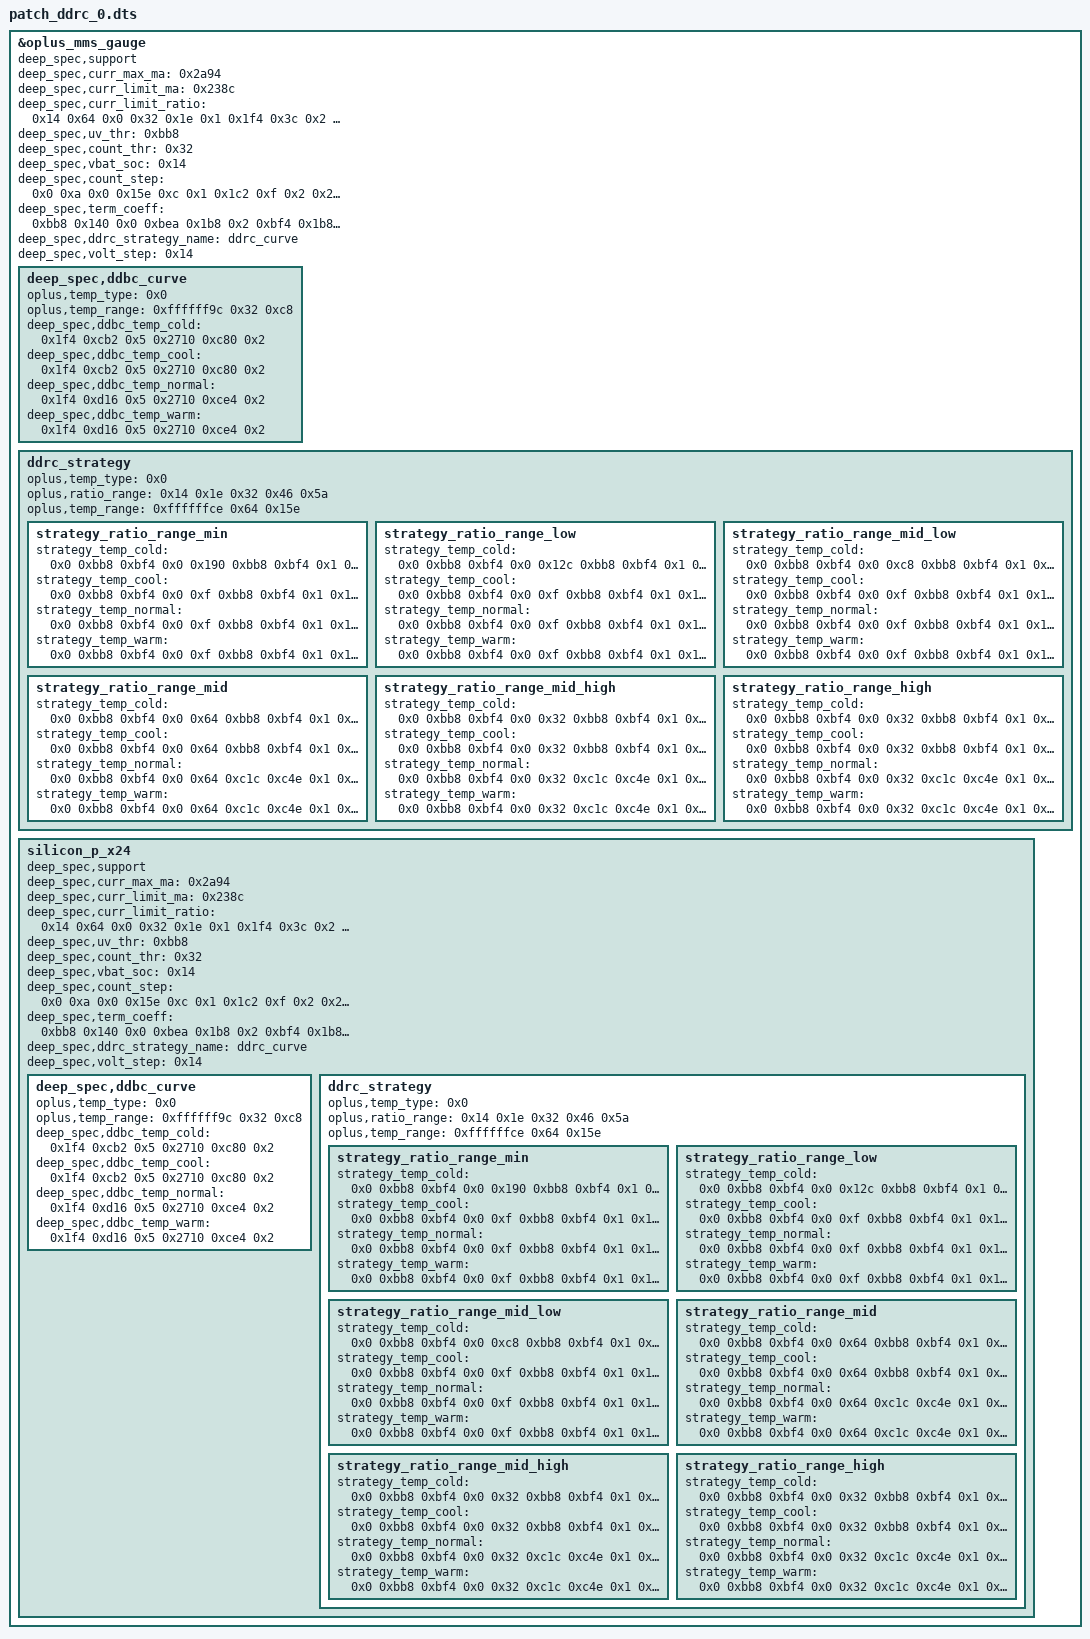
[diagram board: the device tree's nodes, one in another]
/dts-v1/;
/plugin/;

/ {
	fragment@0 {
		target = <&oplus_mms_gauge>;
		__overlay__ {
			deep_spec,support;
			deep_spec,curr_max_ma = <0x2a94>;
			deep_spec,curr_limit_ma = <0x238c>;
			deep_spec,curr_limit_ratio = <0x14 0x64 0x0 0x32 0x1e 0x1 0x1f4 0x3c 0x2 0x1f4 0x3c 0x3>;
			deep_spec,uv_thr = <0xbb8>;
			deep_spec,count_thr = <0x32>;
			deep_spec,vbat_soc = <0x14>;
			deep_spec,count_step = <0x0 0xa 0x0 0x15e 0xc 0x1 0x1c2 0xf 0x2 0x212 0x14 0x3>;
			deep_spec,term_coeff = <0xbb8 0x140 0x0 0xbea 0x1b8 0x2 0xbf4 0x1b8 0x2 0xc4e 0x21c 0x4 0xcb2 0x244 0x5 0xd16 0x258 0x7>;
			deep_spec,ddrc_strategy_name = "ddrc_curve";
			deep_spec,volt_step = <0x14>;
			
			deep_spec,ddbc_curve {
				oplus,temp_type = <0x0>;
				oplus,temp_range = <0xffffff9c 0x32 0xc8>;
				deep_spec,ddbc_temp_cold = <0x1f4 0xcb2 0x5 0x2710 0xc80 0x2>;
				deep_spec,ddbc_temp_cool = <0x1f4 0xcb2 0x5 0x2710 0xc80 0x2>;
				deep_spec,ddbc_temp_normal = <0x1f4 0xd16 0x5 0x2710 0xce4 0x2>;
				deep_spec,ddbc_temp_warm = <0x1f4 0xd16 0x5 0x2710 0xce4 0x2>;
			};
			
			ddrc_strategy {
				oplus,temp_type = <0x0>;
				oplus,ratio_range = <0x14 0x1e 0x32 0x46 0x5a>;
				oplus,temp_range = <0xffffffce 0x64 0x15e>;
				
				strategy_ratio_range_min {
					strategy_temp_cold = <0x0 0xbb8 0xbf4 0x0 0x190 0xbb8 0xbf4 0x1 0x320 0xbb8 0xbf4 0x2 0x4b0 0xc1c 0xc4e 0x3 0x640 0xc80 0xcb2 0x4 0x7d0 0xce4 0xd16 0x5>;
					strategy_temp_cool = <0x0 0xbb8 0xbf4 0x0 0xf 0xbb8 0xbf4 0x1 0x1f4 0xbb8 0xbf4 0x2 0x3e8 0xc1c 0xc4e 0x3 0x5dc 0xc80 0xcb2 0x4 0x7d0 0xce4 0xd16 0x5>;
					strategy_temp_normal = <0x0 0xbb8 0xbf4 0x0 0xf 0xbb8 0xbf4 0x1 0x1f4 0xc1c 0xc4e 0x2 0x3e8 0xc80 0xcb2 0x3 0x5dc 0xce4 0xd16 0x4>;
					strategy_temp_warm = <0x0 0xbb8 0xbf4 0x0 0xf 0xbb8 0xbf4 0x1 0x1f4 0xc1c 0xc4e 0x2 0x3e8 0xc80 0xcb2 0x3 0x5dc 0xce4 0xd16 0x4>;
				};
				
				strategy_ratio_range_low {
					strategy_temp_cold = <0x0 0xbb8 0xbf4 0x0 0x12c 0xbb8 0xbf4 0x1 0x258 0xbb8 0xbf4 0x2 0x384 0xc1c 0xc4e 0x3 0x4b0 0xc80 0xcb2 0x4 0x640 0xce4 0xd16 0x5>;
					strategy_temp_cool = <0x0 0xbb8 0xbf4 0x0 0xf 0xbb8 0xbf4 0x1 0x190 0xbb8 0xbf4 0x2 0x320 0xc1c 0xc4e 0x3 0x4b0 0xc80 0xcb2 0x4 0x640 0xce4 0xd16 0x5>;
					strategy_temp_normal = <0x0 0xbb8 0xbf4 0x0 0xf 0xbb8 0xbf4 0x1 0x190 0xc1c 0xc4e 0x2 0x320 0xc80 0xcb2 0x3 0x4b0 0xce4 0xd16 0x4>;
					strategy_temp_warm = <0x0 0xbb8 0xbf4 0x0 0xf 0xbb8 0xbf4 0x1 0x190 0xc1c 0xc4e 0x2 0x320 0xc80 0xcb2 0x3 0x4b0 0xce4 0xd16 0x4>;
				};
				
				strategy_ratio_range_mid_low {
					strategy_temp_cold = <0x0 0xbb8 0xbf4 0x0 0xc8 0xbb8 0xbf4 0x1 0x190 0xbb8 0xbf4 0x2 0x258 0xc1c 0xc4e 0x3 0x384 0xc80 0xcb2 0x4 0x4b0 0xce4 0xd16 0x5>;
					strategy_temp_cool = <0x0 0xbb8 0xbf4 0x0 0xf 0xbb8 0xbf4 0x1 0x12c 0xbb8 0xbf4 0x2 0x258 0xc1c 0xc4e 0x3 0x384 0xc80 0xcb2 0x4 0x4b0 0xce4 0xd16 0x5>;
					strategy_temp_normal = <0x0 0xbb8 0xbf4 0x0 0xf 0xbb8 0xbf4 0x1 0x12c 0xc1c 0xc4e 0x2 0x258 0xc80 0xcb2 0x3 0x384 0xce4 0xd16 0x4>;
					strategy_temp_warm = <0x0 0xbb8 0xbf4 0x0 0xf 0xbb8 0xbf4 0x1 0x12c 0xc1c 0xc4e 0x2 0x258 0xc80 0xcb2 0x3 0x384 0xce4 0xd16 0x4>;
				};
				
				strategy_ratio_range_mid {
					strategy_temp_cold = <0x0 0xbb8 0xbf4 0x0 0x64 0xbb8 0xbf4 0x1 0x12c 0xbb8 0xbf4 0x2 0x1f4 0xc1c 0xc4e 0x3 0x2bc 0xc80 0xcb2 0x4 0x384 0xce4 0xd16 0x5>;
					strategy_temp_cool = <0x0 0xbb8 0xbf4 0x0 0x64 0xbb8 0xbf4 0x1 0x12c 0xc1c 0xc4e 0x2 0x258 0xc80 0xcb2 0x3 0x384 0xce4 0xd16 0x4>;
					strategy_temp_normal = <0x0 0xbb8 0xbf4 0x0 0x64 0xc1c 0xc4e 0x1 0x12c 0xc80 0xcb2 0x2 0x258 0xce4 0xd16 0x3>;
					strategy_temp_warm = <0x0 0xbb8 0xbf4 0x0 0x64 0xc1c 0xc4e 0x1 0x12c 0xc80 0xcb2 0x2 0x258 0xce4 0xd16 0x3>;
				};
				
				strategy_ratio_range_mid_high {
					strategy_temp_cold = <0x0 0xbb8 0xbf4 0x0 0x32 0xbb8 0xbf4 0x1 0x64 0xbb8 0xbf4 0x2 0x96 0xc1c 0xc4e 0x3 0x12c 0xc80 0xcb2 0x4 0x1f4 0xce4 0xd16 0x5>;
					strategy_temp_cool = <0x0 0xbb8 0xbf4 0x0 0x32 0xbb8 0xbf4 0x1 0x64 0xc1c 0xc4e 0x2 0x96 0xc80 0xcb2 0x3 0x12c 0xce4 0xd16 0x4>;
					strategy_temp_normal = <0x0 0xbb8 0xbf4 0x0 0x32 0xc1c 0xc4e 0x1 0x64 0xc80 0xcb2 0x2 0x96 0xce4 0xd16 0x3>;
					strategy_temp_warm = <0x0 0xbb8 0xbf4 0x0 0x32 0xc1c 0xc4e 0x1 0x64 0xc80 0xcb2 0x2 0x96 0xce4 0xd16 0x3>;
				};
				
				strategy_ratio_range_high {
					strategy_temp_cold = <0x0 0xbb8 0xbf4 0x0 0x32 0xbb8 0xbf4 0x1 0x64 0xbb8 0xbf4 0x2 0x96 0xc1c 0xc4e 0x3 0x12c 0xc80 0xcb2 0x4 0x1f4 0xce4 0xd16 0x5>;
					strategy_temp_cool = <0x0 0xbb8 0xbf4 0x0 0x32 0xbb8 0xbf4 0x1 0x64 0xc1c 0xc4e 0x2 0x96 0xc80 0xcb2 0x3 0x12c 0xce4 0xd16 0x4>;
					strategy_temp_normal = <0x0 0xbb8 0xbf4 0x0 0x32 0xc1c 0xc4e 0x1 0x64 0xc80 0xcb2 0x2 0x96 0xce4 0xd16 0x3>;
					strategy_temp_warm = <0x0 0xbb8 0xbf4 0x0 0x32 0xc1c 0xc4e 0x1 0x64 0xc80 0xcb2 0x2 0x96 0xce4 0xd16 0x3>;
				};
			};
			
			silicon_p_x24 {
				deep_spec,support;
				deep_spec,curr_max_ma = <0x2a94>;
				deep_spec,curr_limit_ma = <0x238c>;
				deep_spec,curr_limit_ratio = <0x14 0x64 0x0 0x32 0x1e 0x1 0x1f4 0x3c 0x2 0x1f4 0x3c 0x3>;
				deep_spec,uv_thr = <0xbb8>;
				deep_spec,count_thr = <0x32>;
				deep_spec,vbat_soc = <0x14>;
				deep_spec,count_step = <0x0 0xa 0x0 0x15e 0xc 0x1 0x1c2 0xf 0x2 0x212 0x14 0x3>;
				deep_spec,term_coeff = <0xbb8 0x140 0x0 0xbea 0x1b8 0x2 0xbf4 0x1b8 0x2 0xc4e 0x21c 0x4 0xcb2 0x244 0x5 0xd16 0x258 0x7>;
				deep_spec,ddrc_strategy_name = "ddrc_curve";
				deep_spec,volt_step = <0x14>;
				
				deep_spec,ddbc_curve {
					oplus,temp_type = <0x0>;
					oplus,temp_range = <0xffffff9c 0x32 0xc8>;
					deep_spec,ddbc_temp_cold = <0x1f4 0xcb2 0x5 0x2710 0xc80 0x2>;
					deep_spec,ddbc_temp_cool = <0x1f4 0xcb2 0x5 0x2710 0xc80 0x2>;
					deep_spec,ddbc_temp_normal = <0x1f4 0xd16 0x5 0x2710 0xce4 0x2>;
					deep_spec,ddbc_temp_warm = <0x1f4 0xd16 0x5 0x2710 0xce4 0x2>;
				};
				
				ddrc_strategy {
					oplus,temp_type = <0x0>;
					oplus,ratio_range = <0x14 0x1e 0x32 0x46 0x5a>;
					oplus,temp_range = <0xffffffce 0x64 0x15e>;
					
					strategy_ratio_range_min {
						strategy_temp_cold = <0x0 0xbb8 0xbf4 0x0 0x190 0xbb8 0xbf4 0x1 0x320 0xbb8 0xbf4 0x2 0x4b0 0xc1c 0xc4e 0x3 0x640 0xc80 0xcb2 0x4 0x7d0 0xce4 0xd16 0x5>;
						strategy_temp_cool = <0x0 0xbb8 0xbf4 0x0 0xf 0xbb8 0xbf4 0x1 0x1f4 0xbb8 0xbf4 0x2 0x3e8 0xc1c 0xc4e 0x3 0x5dc 0xc80 0xcb2 0x4 0x7d0 0xce4 0xd16 0x5>;
						strategy_temp_normal = <0x0 0xbb8 0xbf4 0x0 0xf 0xbb8 0xbf4 0x1 0x1f4 0xc1c 0xc4e 0x2 0x3e8 0xc80 0xcb2 0x3 0x5dc 0xce4 0xd16 0x4>;
						strategy_temp_warm = <0x0 0xbb8 0xbf4 0x0 0xf 0xbb8 0xbf4 0x1 0x1f4 0xc1c 0xc4e 0x2 0x3e8 0xc80 0xcb2 0x3 0x5dc 0xce4 0xd16 0x4>;
					};
					
					strategy_ratio_range_low {
						strategy_temp_cold = <0x0 0xbb8 0xbf4 0x0 0x12c 0xbb8 0xbf4 0x1 0x258 0xbb8 0xbf4 0x2 0x384 0xc1c 0xc4e 0x3 0x4b0 0xc80 0xcb2 0x4 0x640 0xce4 0xd16 0x5>;
						strategy_temp_cool = <0x0 0xbb8 0xbf4 0x0 0xf 0xbb8 0xbf4 0x1 0x190 0xbb8 0xbf4 0x2 0x320 0xc1c 0xc4e 0x3 0x4b0 0xc80 0xcb2 0x4 0x640 0xce4 0xd16 0x5>;
						strategy_temp_normal = <0x0 0xbb8 0xbf4 0x0 0xf 0xbb8 0xbf4 0x1 0x190 0xc1c 0xc4e 0x2 0x320 0xc80 0xcb2 0x3 0x4b0 0xce4 0xd16 0x4>;
						strategy_temp_warm = <0x0 0xbb8 0xbf4 0x0 0xf 0xbb8 0xbf4 0x1 0x190 0xc1c 0xc4e 0x2 0x320 0xc80 0xcb2 0x3 0x4b0 0xce4 0xd16 0x4>;
					};
					
					strategy_ratio_range_mid_low {
						strategy_temp_cold = <0x0 0xbb8 0xbf4 0x0 0xc8 0xbb8 0xbf4 0x1 0x190 0xbb8 0xbf4 0x2 0x258 0xc1c 0xc4e 0x3 0x384 0xc80 0xcb2 0x4 0x4b0 0xce4 0xd16 0x5>;
						strategy_temp_cool = <0x0 0xbb8 0xbf4 0x0 0xf 0xbb8 0xbf4 0x1 0x12c 0xbb8 0xbf4 0x2 0x258 0xc1c 0xc4e 0x3 0x384 0xc80 0xcb2 0x4 0x4b0 0xce4 0xd16 0x5>;
						strategy_temp_normal = <0x0 0xbb8 0xbf4 0x0 0xf 0xbb8 0xbf4 0x1 0x12c 0xc1c 0xc4e 0x2 0x258 0xc80 0xcb2 0x3 0x384 0xce4 0xd16 0x4>;
						strategy_temp_warm = <0x0 0xbb8 0xbf4 0x0 0xf 0xbb8 0xbf4 0x1 0x12c 0xc1c 0xc4e 0x2 0x258 0xc80 0xcb2 0x3 0x384 0xce4 0xd16 0x4>;
					};
					
					strategy_ratio_range_mid {
						strategy_temp_cold = <0x0 0xbb8 0xbf4 0x0 0x64 0xbb8 0xbf4 0x1 0x12c 0xbb8 0xbf4 0x2 0x1f4 0xc1c 0xc4e 0x3 0x2bc 0xc80 0xcb2 0x4 0x384 0xce4 0xd16 0x5>;
						strategy_temp_cool = <0x0 0xbb8 0xbf4 0x0 0x64 0xbb8 0xbf4 0x1 0x12c 0xc1c 0xc4e 0x2 0x258 0xc80 0xcb2 0x3 0x384 0xce4 0xd16 0x4>;
						strategy_temp_normal = <0x0 0xbb8 0xbf4 0x0 0x64 0xc1c 0xc4e 0x1 0x12c 0xc80 0xcb2 0x2 0x258 0xce4 0xd16 0x3>;
						strategy_temp_warm = <0x0 0xbb8 0xbf4 0x0 0x64 0xc1c 0xc4e 0x1 0x12c 0xc80 0xcb2 0x2 0x258 0xce4 0xd16 0x3>;
					};
					
					strategy_ratio_range_mid_high {
						strategy_temp_cold = <0x0 0xbb8 0xbf4 0x0 0x32 0xbb8 0xbf4 0x1 0x64 0xbb8 0xbf4 0x2 0x96 0xc1c 0xc4e 0x3 0x12c 0xc80 0xcb2 0x4 0x1f4 0xce4 0xd16 0x5>;
						strategy_temp_cool = <0x0 0xbb8 0xbf4 0x0 0x32 0xbb8 0xbf4 0x1 0x64 0xc1c 0xc4e 0x2 0x96 0xc80 0xcb2 0x3 0x12c 0xce4 0xd16 0x4>;
						strategy_temp_normal = <0x0 0xbb8 0xbf4 0x0 0x32 0xc1c 0xc4e 0x1 0x64 0xc80 0xcb2 0x2 0x96 0xce4 0xd16 0x3>;
						strategy_temp_warm = <0x0 0xbb8 0xbf4 0x0 0x32 0xc1c 0xc4e 0x1 0x64 0xc80 0xcb2 0x2 0x96 0xce4 0xd16 0x3>;
					};
					
					strategy_ratio_range_high {
						strategy_temp_cold = <0x0 0xbb8 0xbf4 0x0 0x32 0xbb8 0xbf4 0x1 0x64 0xbb8 0xbf4 0x2 0x96 0xc1c 0xc4e 0x3 0x12c 0xc80 0xcb2 0x4 0x1f4 0xce4 0xd16 0x5>;
						strategy_temp_cool = <0x0 0xbb8 0xbf4 0x0 0x32 0xbb8 0xbf4 0x1 0x64 0xc1c 0xc4e 0x2 0x96 0xc80 0xcb2 0x3 0x12c 0xce4 0xd16 0x4>;
						strategy_temp_normal = <0x0 0xbb8 0xbf4 0x0 0x32 0xc1c 0xc4e 0x1 0x64 0xc80 0xcb2 0x2 0x96 0xce4 0xd16 0x3>;
						strategy_temp_warm = <0x0 0xbb8 0xbf4 0x0 0x32 0xc1c 0xc4e 0x1 0x64 0xc80 0xcb2 0x2 0x96 0xce4 0xd16 0x3>;
					};
				};
			};
		};
	};
};
